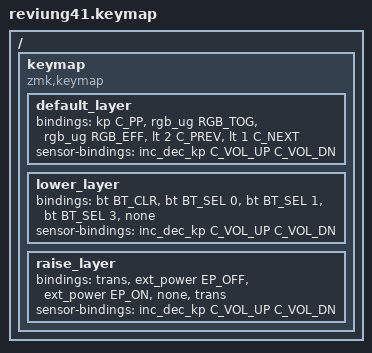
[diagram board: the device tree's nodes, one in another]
/*
 * Copyright (c) 2020 The ZMK Contributors
 *
 * SPDX-License-Identifier: MIT
 */

#include <behaviors.dtsi>
#include <dt-bindings/zmk/keys.h>
#include <dt-bindings/zmk/bt.h>
#include <dt-bindings/zmk/rgb.h>
#include <dt-bindings/zmk/outputs.h>
#include <dt-bindings/zmk/ext_power.h>

// Layers
#define DEFAULT    0       // default_layer
#define LOWER      1       // lower_layer
#define RAISE      2       // raise_layer

/ {

        keymap {
                compatible = "zmk,keymap";

                default_layer {
// -------------------------------------------------------------------------------------
// |  ESC         |  Q  |  W  |  E  |  R  |
                        bindings = <
   &kp C_PP         &rgb_ug RGB_TOG &rgb_ug RGB_EFF &lt 2 C_PREV &lt 1 C_NEXT 
                        >;
			sensor-bindings = <&inc_dec_kp C_VOL_UP C_VOL_DN>;
                };

                lower_layer {
// ----------------------------------------------------------------------------------
// |     |  1      |  2        |  3     |  4     |
                        bindings = <
   &bt BT_CLR  &bt BT_SEL 0   &bt BT_SEL 1   &bt BT_SEL 3   &none  
                        >;
			sensor-bindings = <&inc_dec_kp C_VOL_UP C_VOL_DN>;
                };

                raise_layer {
// -----------------------------------------------------------------------------------------
// |     | 1       | 2       | 3       | 4       |
                        bindings = <
   &trans   &ext_power EP_OFF    &ext_power EP_ON    &none  &trans     
                        >;
			sensor-bindings = <&inc_dec_kp C_VOL_UP C_VOL_DN>;

                };
        };
};
